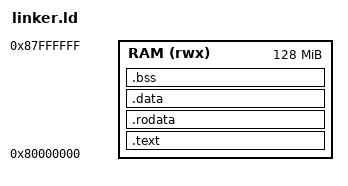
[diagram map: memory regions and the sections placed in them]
OUTPUT_ARCH(riscv)
ENTRY(_start)

MEMORY
{
    RAM (rwx) : ORIGIN = 0x80000000, LENGTH = 128M
}

SECTIONS
{
    .text : ALIGN(4) {
        KEEP(*(.text.init))
        *(.text .text.*)
    } > RAM

    .rodata : ALIGN(4) {
        *(.rodata .rodata.*)
    } > RAM

    .data : ALIGN(4) {
        *(.data .data.*)
    } > RAM

    .bss : ALIGN(4) {
        *(.bss .bss.*)
        *(COMMON)
    } > RAM

    _sstack = ORIGIN(RAM) + LENGTH(RAM);

    /DISCARD/ : {
        *(.comment)
        *(.note*)
        *(.eh_frame*)
        *(.riscv.attributes)
    }
}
